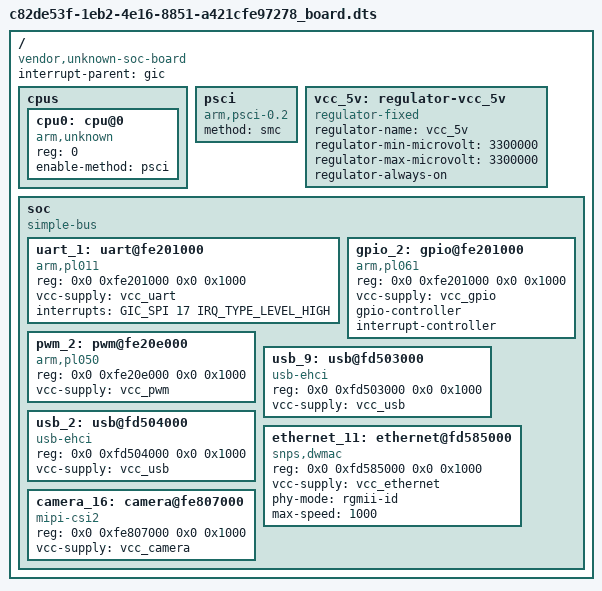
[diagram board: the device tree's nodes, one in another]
/dts-v1/;

/* Generated by @dt_architect — PDF-to-Gadget Pipeline
 * SoC  : Unknown SoC
 * Arch : arm64 (Unknown)
 * Date : auto-generated
 */

#include <dt-bindings/interrupt-controller/arm-gic.h>
#include <dt-bindings/gpio/gpio.h>

/ {
	compatible = "vendor,unknown-soc-board", "vendor,unknown-soc";
	#address-cells = <2>;
	#size-cells = <2>;
	interrupt-parent = <&gic>;

	cpus {
		#address-cells = <1>;
		#size-cells = <0>;

		cpu0: cpu@0 {
			device_type = "cpu";
			compatible = "arm,unknown";
			reg = <0>;
			enable-method = "psci";
		};
	};

	psci {
		compatible = "arm,psci-0.2";
		method = "smc";
	};

	/* ── Power Regulators ─────────────────────────────── */
	vcc_5v: regulator-vcc_5v {
		compatible = "regulator-fixed";
		regulator-name = "vcc_5v";
		regulator-min-microvolt = <3300000>;
		regulator-max-microvolt = <3300000>;
		regulator-always-on;
	};

	/* ── Simple Bus ──────────────────────────────────── */
	soc: soc {
		compatible = "simple-bus";
		#address-cells = <2>;
		#size-cells = <2>;
		ranges;

		uart_1: uart@fe201000 {
			compatible = "arm,pl011";
			reg = <0x0 0xfe201000 0x0 0x1000>;
			#address-cells = <1>;
			#size-cells = <0>;
			status = "okay";
			vcc-supply = <&vcc_uart>;
			/* UART peripheral on UART1 */
			clock-names = "uartclk", "apb_pclk";
			interrupts = <GIC_SPI 17 IRQ_TYPE_LEVEL_HIGH>;
		};

		gpio_2: gpio@fe201000 {
			compatible = "arm,pl061";
			reg = <0x0 0xfe201000 0x0 0x1000>;
			#address-cells = <1>;
			#size-cells = <0>;
			status = "okay";
			vcc-supply = <&vcc_gpio>;
			/* GPIO peripheral on GPIO2 */
			gpio-controller;
			#gpio-cells = <2>;
			interrupt-controller;
			#interrupt-cells = <2>;
		};

		pwm_2: pwm@fe20e000 {
			compatible = "arm,pl050";
			reg = <0x0 0xfe20e000 0x0 0x1000>;
			#address-cells = <1>;
			#size-cells = <0>;
			status = "okay";
			vcc-supply = <&vcc_pwm>;
			/* PWM peripheral on PWM2 */
		};

		usb_9: usb@fd503000 {
			compatible = "usb-ehci";
			reg = <0x0 0xfd503000 0x0 0x1000>;
			#address-cells = <1>;
			#size-cells = <0>;
			status = "okay";
			vcc-supply = <&vcc_usb>;
			/* USB peripheral on USB */
		};

		usb_2: usb@fd504000 {
			compatible = "usb-ehci";
			reg = <0x0 0xfd504000 0x0 0x1000>;
			#address-cells = <1>;
			#size-cells = <0>;
			status = "okay";
			vcc-supply = <&vcc_usb>;
			/* USB peripheral on USB2 */
		};

		ethernet_11: ethernet@fd585000 {
			compatible = "snps,dwmac";
			reg = <0x0 0xfd585000 0x0 0x1000>;
			#address-cells = <1>;
			#size-cells = <0>;
			status = "okay";
			vcc-supply = <&vcc_ethernet>;
			/* ETHERNET peripheral on ETHERNET */
			clock-names = "stmmaceth", "pclk", "ptp_ref";
			phy-mode = "rgmii-id";
			max-speed = <1000>;
		};

		camera_16: camera@fe807000 {
			compatible = "mipi-csi2";
			reg = <0x0 0xfe807000 0x0 0x1000>;
			#address-cells = <1>;
			#size-cells = <0>;
			status = "okay";
			vcc-supply = <&vcc_camera>;
			/* CAMERA peripheral on CAMERA */
		};
	};
};
